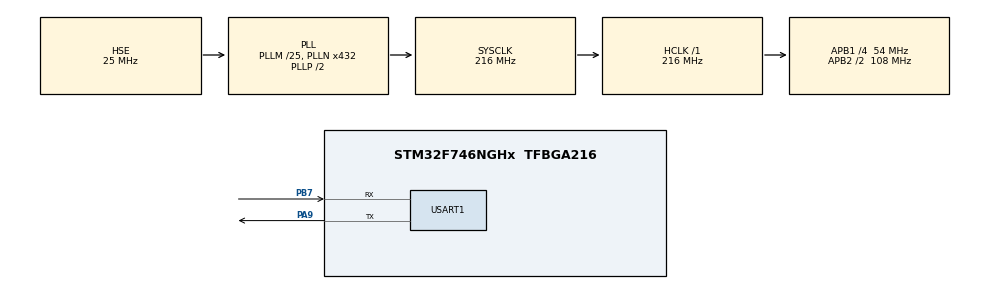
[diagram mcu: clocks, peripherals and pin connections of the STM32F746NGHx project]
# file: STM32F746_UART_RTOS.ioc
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CORTEX_M7.CPU_DCache=Enabled
CORTEX_M7.CPU_ICache=Enabled
CORTEX_M7.PREFETCH_ENABLE=1
FREERTOS.Tasks01=myTask01,24,256,uart_task_1,Default,NULL,Dynamic,NULL,NULL;myTask02,24,256,uart_task_2,Default,NULL,Dynamic,NULL,NULL;myTask03,16,256,sobra_cpu,Default,NULL,Dynamic,NULL,NULL
FREERTOS.configENABLE_FPU=1
FREERTOS.configMAX_TASK_NAME_LEN=32
FREERTOS.configTOTAL_HEAP_SIZE=65536
Mcu.Family=STM32F7
Mcu.Name=STM32F746NGHx
Mcu.Package=TFBGA216
NVIC.PriorityGroup=NVIC_PRIORITYGROUP_4
NVIC.TIM1_UP_TIM10_IRQn=true\:0\:0\:false\:false\:true\:false\:false\:true
NVIC.TimeBase=TIM1_UP_TIM10_IRQn
NVIC.TimeBaseIP=TIM1
NVIC.USART1_IRQn=true\:5\:0\:false\:false\:true\:true\:true\:true
PA9.Mode=Asynchronous
PA9.Signal=USART1_TX
PB7.Mode=Asynchronous
PB7.Signal=USART1_RX
PH0/OSC_IN.Mode=HSE-External-Oscillator
PH0/OSC_IN.Signal=RCC_OSC_IN
PH1/OSC_OUT.Mode=HSE-External-Oscillator
PH1/OSC_OUT.Signal=RCC_OSC_OUT
ProjectManager.HeapSize=0x200
ProjectManager.StackSize=0x400
ProjectManager.TargetToolchain=STM32CubeIDE
RCC.AHBFreq_Value=216000000
RCC.APB1CLKDivider=RCC_HCLK_DIV4
RCC.APB1Freq_Value=54000000
RCC.APB1TimFreq_Value=108000000
RCC.APB2CLKDivider=RCC_HCLK_DIV2
RCC.APB2Freq_Value=108000000
RCC.APB2TimFreq_Value=216000000
RCC.CortexFreq_Value=216000000
RCC.HCLKFreq_Value=216000000
RCC.HSE_VALUE=25000000
RCC.HSI_VALUE=16000000
RCC.LSE_VALUE=32768
RCC.PLLM=25
RCC.PLLN=432
RCC.PLLSourceVirtual=RCC_PLLSOURCE_HSE
RCC.SYSCLKFreq_VALUE=216000000
RCC.SYSCLKSource=RCC_SYSCLKSOURCE_PLLCLK
RCC.USBFreq_Value=216000000
RCC.VCOOutputFreq_Value=432000000
USART1.VirtualMode-Asynchronous=VM_ASYNC
VP_FREERTOS_VS_CMSIS_V2.Mode=CMSIS_V2
VP_SYS_VS_tim1.Mode=TIM1
board=custom

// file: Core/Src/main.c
/* USER CODE BEGIN Header */
/**
  ******************************************************************************
  * @file           : main.c
  * @brief          : Main program body
  ******************************************************************************
  * @attention
  *
  * <h2><center>&copy; Copyright (c) 2020 STMicroelectronics.
  * All rights reserved.</center></h2>
  *
  * This software component is licensed by ST under BSD 3-Clause license,
  * the "License"; You may not use this file except in compliance with the
  * License. You may obtain a copy of the License at:
  *                        opensource.org/licenses/BSD-3-Clause
  *
  ******************************************************************************
  */
/* USER CODE END Header */

#include "main.h"
#include "cmsis_os.h"

/* USER CODE BEGIN Includes */
#include "semphr.h"
/* USER CODE END Includes */

/* USER CODE BEGIN PD */
#define USE_SEMAPHR	1
#define USE_TASKNOTIFY	0
#define USE_MUTEX	1
/* USER CODE END PD */

UART_HandleTypeDef huart1;

/* Definitions for myTask01 */
osThreadId_t myTask01Handle;
const osThreadAttr_t myTask01_attributes = {
  .name = "myTask01",
  .priority = (osPriority_t) osPriorityNormal,
  .stack_size = 256 * 4
};
/* Definitions for myTask02 */
osThreadId_t myTask02Handle;
const osThreadAttr_t myTask02_attributes = {
  .name = "myTask02",
  .priority = (osPriority_t) osPriorityNormal,
  .stack_size = 256 * 4
};
/* Definitions for myTask03 */
osThreadId_t myTask03Handle;
const osThreadAttr_t myTask03_attributes = {
  .name = "myTask03",
  .priority = (osPriority_t) osPriorityBelowNormal,
  .stack_size = 256 * 4
};

void SystemClock_Config(void);
static void MX_GPIO_Init(void);
static void MX_USART1_UART_Init(void);
void uart_task_1(void *argument);
void uart_task_2(void *argument);
void sobra_cpu(void *argument);

/* USER CODE BEGIN 0 */
volatile int counter1 = 0;
volatile int counter2 = 0;
#if (USE_MUTEX == 1)
SemaphoreHandle_t mutexTx;
#endif
#if (USE_SEMAPHR == 1)
#if (USE_TASKNOTIFY == 1)
static TaskHandle_t xTaskToNotify = NULL;
#else
SemaphoreHandle_t sUART1;
#endif
void HAL_UART_TxCpltCallback(UART_HandleTypeDef *huart){
	signed portBASE_TYPE pxHigherPriorityTaskWokenTX = pdFALSE;
#if (USE_TASKNOTIFY == 1)
	vTaskNotifyGiveFromISR(xTaskToNotify, &pxHigherPriorityTaskWokenTX);
#else
	xSemaphoreGiveFromISR(sUART1, &pxHigherPriorityTaskWokenTX);
#endif
	if (pxHigherPriorityTaskWokenTX == pdTRUE)
	{
		portYIELD();
	}
}
#endif
/* USER CODE END 0 */

int main(void)
{

  /* Enable I-Cache---------------------------------------------------------*/
  SCB_EnableICache();

  /* Enable D-Cache---------------------------------------------------------*/
  SCB_EnableDCache();

  /* MCU Configuration--------------------------------------------------------*/

  /* Reset of all peripherals, Initializes the Flash interface and the Systick. */
  HAL_Init();

  /* Configure the system clock */
  SystemClock_Config();

  /* Initialize all configured peripherals */
  MX_GPIO_Init();
  MX_USART1_UART_Init();

  /* Init scheduler */
  osKernelInitialize();

  /* Create the thread(s) */
  /* creation of myTask01 */
  myTask01Handle = osThreadNew(uart_task_1, NULL, &myTask01_attributes);

  /* creation of myTask02 */
  myTask02Handle = osThreadNew(uart_task_2, NULL, &myTask02_attributes);

  /* creation of myTask03 */
  myTask03Handle = osThreadNew(sobra_cpu, NULL, &myTask03_attributes);

  /* USER CODE BEGIN RTOS_THREADS */
  /* add threads, ... */
#if (USE_SEMAPHR == 1)
#if (USE_TASKNOTIFY == 0)
  sUART1 = xSemaphoreCreateBinary();
#endif
#endif
#if (USE_MUTEX == 1)
  mutexTx = xSemaphoreCreateMutex();
#endif
  /* USER CODE END RTOS_THREADS */

  /* Start scheduler */
  osKernelStart();

  /* We should never get here as control is now taken by the scheduler */
  /* Infinite loop */
  while (1)
  {

  }
}

void SystemClock_Config(void)
{
  RCC_OscInitTypeDef RCC_OscInitStruct = {0};
  RCC_ClkInitTypeDef RCC_ClkInitStruct = {0};
  RCC_PeriphCLKInitTypeDef PeriphClkInitStruct = {0};

  /** Configure the main internal regulator output voltage
  */
  __HAL_RCC_PWR_CLK_ENABLE();
  __HAL_PWR_VOLTAGESCALING_CONFIG(PWR_REGULATOR_VOLTAGE_SCALE1);
  /** Initializes the CPU, AHB and APB busses clocks
  */
  RCC_OscInitStruct.OscillatorType = RCC_OSCILLATORTYPE_HSE;
  RCC_OscInitStruct.HSEState = RCC_HSE_ON;
  RCC_OscInitStruct.PLL.PLLState = RCC_PLL_ON;
  RCC_OscInitStruct.PLL.PLLSource = RCC_PLLSOURCE_HSE;
  RCC_OscInitStruct.PLL.PLLM = 25;
  RCC_OscInitStruct.PLL.PLLN = 432;
  RCC_OscInitStruct.PLL.PLLP = RCC_PLLP_DIV2;
  RCC_OscInitStruct.PLL.PLLQ = 2;
  if (HAL_RCC_OscConfig(&RCC_OscInitStruct) != HAL_OK)
  {
    Error_Handler();
  }
  /** Activate the Over-Drive mode
  */
  if (HAL_PWREx_EnableOverDrive() != HAL_OK)
  {
    Error_Handler();
  }
  /** Initializes the CPU, AHB and APB busses clocks
  */
  RCC_ClkInitStruct.ClockType = RCC_CLOCKTYPE_HCLK|RCC_CLOCKTYPE_SYSCLK
                              |RCC_CLOCKTYPE_PCLK1|RCC_CLOCKTYPE_PCLK2;
  RCC_ClkInitStruct.SYSCLKSource = RCC_SYSCLKSOURCE_PLLCLK;
  RCC_ClkInitStruct.AHBCLKDivider = RCC_SYSCLK_DIV1;
  RCC_ClkInitStruct.APB1CLKDivider = RCC_HCLK_DIV4;
  RCC_ClkInitStruct.APB2CLKDivider = RCC_HCLK_DIV2;

  if (HAL_RCC_ClockConfig(&RCC_ClkInitStruct, FLASH_LATENCY_7) != HAL_OK)
  {
    Error_Handler();
  }
  PeriphClkInitStruct.PeriphClockSelection = RCC_PERIPHCLK_USART1;
  PeriphClkInitStruct.Usart1ClockSelection = RCC_USART1CLKSOURCE_PCLK2;
  if (HAL_RCCEx_PeriphCLKConfig(&PeriphClkInitStruct) != HAL_OK)
  {
    Error_Handler();
  }
}

static void MX_USART1_UART_Init(void)
{

  huart1.Instance = USART1;
  huart1.Init.BaudRate = 115200;
  huart1.Init.WordLength = UART_WORDLENGTH_8B;
  huart1.Init.StopBits = UART_STOPBITS_1;
  huart1.Init.Parity = UART_PARITY_NONE;
  huart1.Init.Mode = UART_MODE_TX_RX;
  huart1.Init.HwFlowCtl = UART_HWCONTROL_NONE;
  huart1.Init.OverSampling = UART_OVERSAMPLING_16;
  huart1.Init.OneBitSampling = UART_ONE_BIT_SAMPLE_DISABLE;
  huart1.AdvancedInit.AdvFeatureInit = UART_ADVFEATURE_NO_INIT;
  if (HAL_UART_Init(&huart1) != HAL_OK)
  {
    Error_Handler();
  }

}

static void MX_GPIO_Init(void)
{

  /* GPIO Ports Clock Enable */
  __HAL_RCC_GPIOB_CLK_ENABLE();
  __HAL_RCC_GPIOA_CLK_ENABLE();
  __HAL_RCC_GPIOH_CLK_ENABLE();

}

void uart_task_1(void *argument)
{
  /* USER CODE BEGIN 5 */
  uint8_t *string = (uint8_t *)"Olá Mundo da Tarefa 1!\n\r";
  /* Infinite loop */
  for(;;)
  {
#if (USE_MUTEX == 1)
	if (xSemaphoreTake(mutexTx, portMAX_DELAY) == pdTRUE){
#endif
		//HAL_UART_Transmit(&huart1, string, 25, 1000);
		HAL_UART_Transmit_IT(&huart1, string, 25);
#if (USE_SEMAPHR == 1)
		// Wait indefinitely for a UART interrupt
#if (USE_TASKNOTIFY == 1)
		xTaskToNotify = xTaskGetCurrentTaskHandle();
		ulTaskNotifyTake(pdTRUE, portMAX_DELAY);
#else
		xSemaphoreTake(sUART1, portMAX_DELAY);
#endif
#endif
#if (USE_MUTEX == 1)
	}
	xSemaphoreGive(mutexTx);
#endif
    //osDelay(3);
	taskYIELD();
  }
  /* USER CODE END 5 */
}

void uart_task_2(void *argument)
{
  /* USER CODE BEGIN uart_task_2 */
  uint8_t *string2 = (uint8_t *)"Olá Mundo da Tarefa 2!\n\r";
  /* Infinite loop */
  for(;;)
  {
#if (USE_MUTEX == 1)
	if (xSemaphoreTake(mutexTx, portMAX_DELAY) == pdTRUE){
#endif
		//HAL_UART_Transmit(&huart1, string2, 25, 1000);
		HAL_UART_Transmit_IT(&huart1, string2, 25);
#if (USE_SEMAPHR == 1)
		// Wait indefinitely for a UART interrupt
#if (USE_TASKNOTIFY == 1)
		xTaskToNotify = xTaskGetCurrentTaskHandle();
		ulTaskNotifyTake(pdTRUE, portMAX_DELAY);
#else
		xSemaphoreTake(sUART1, portMAX_DELAY);
#endif
#endif
#if (USE_MUTEX == 1)
	}
	xSemaphoreGive(mutexTx);
#endif
    //osDelay(3);
	taskYIELD();
  }
  /* USER CODE END uart_task_2 */
}

/* USER CODE BEGIN Header_sobra_cpu */
volatile int count = 0;
/**
* @brief Function implementing the myTask03 thread.
* @param argument: Not used
* @retval None
*/
/* USER CODE END Header_sobra_cpu */
void sobra_cpu(void *argument)
{
  /* USER CODE BEGIN sobra_cpu */
  int i = 0;
  int result = 0;
  /* Infinite loop */
  for(;;)
  {
	for(i=0;i<1024;i++){
		result = result ^ i;
	}
	count++;
  }
  /* USER CODE END sobra_cpu */
}

 /**
  * @brief  Period elapsed callback in non blocking mode
  * @note   This function is called  when TIM1 interrupt took place, inside
  * HAL_TIM_IRQHandler(). It makes a direct call to HAL_IncTick() to increment
  * a global variable "uwTick" used as application time base.
  * @param  htim : TIM handle
  * @retval None
  */
void HAL_TIM_PeriodElapsedCallback(TIM_HandleTypeDef *htim)
{
  /* USER CODE BEGIN Callback 0 */
  if (HAL_GetTick() >= 1000){
	  count = 0;
  }
  /* USER CODE END Callback 0 */
  if (htim->Instance == TIM1) {
    HAL_IncTick();
  }
}

void Error_Handler(void)
{
}

/************************ (C) COPYRIGHT STMicroelectronics *****END OF FILE****/
